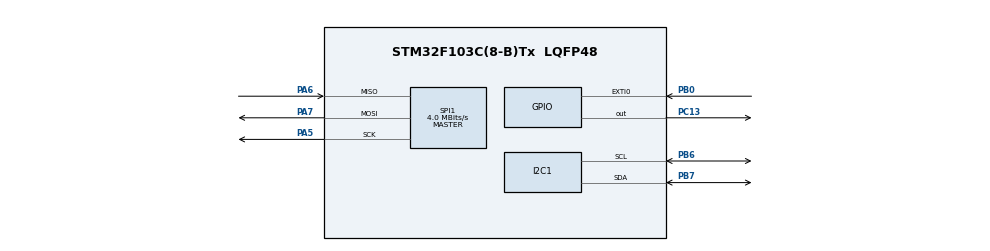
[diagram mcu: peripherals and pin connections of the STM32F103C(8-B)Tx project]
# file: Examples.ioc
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Dma.I2C1_RX.2.Direction=DMA_PERIPH_TO_MEMORY
Dma.I2C1_RX.2.Instance=DMA1_Channel7
Dma.I2C1_RX.2.MemDataAlignment=DMA_MDATAALIGN_BYTE
Dma.I2C1_RX.2.MemInc=DMA_MINC_ENABLE
Dma.I2C1_RX.2.Mode=DMA_NORMAL
Dma.I2C1_RX.2.PeriphDataAlignment=DMA_PDATAALIGN_BYTE
Dma.I2C1_RX.2.PeriphInc=DMA_PINC_DISABLE
Dma.I2C1_RX.2.Priority=DMA_PRIORITY_LOW
Dma.I2C1_TX.3.Direction=DMA_MEMORY_TO_PERIPH
Dma.I2C1_TX.3.Instance=DMA1_Channel6
Dma.I2C1_TX.3.MemDataAlignment=DMA_MDATAALIGN_BYTE
Dma.I2C1_TX.3.MemInc=DMA_MINC_ENABLE
Dma.I2C1_TX.3.Mode=DMA_NORMAL
Dma.I2C1_TX.3.PeriphDataAlignment=DMA_PDATAALIGN_BYTE
Dma.I2C1_TX.3.PeriphInc=DMA_PINC_DISABLE
Dma.I2C1_TX.3.Priority=DMA_PRIORITY_LOW
Dma.Request0=SPI1_RX
Dma.Request1=SPI1_TX
Dma.Request2=I2C1_RX
Dma.Request3=I2C1_TX
Dma.SPI1_RX.0.Direction=DMA_PERIPH_TO_MEMORY
Dma.SPI1_RX.0.Instance=DMA1_Channel2
Dma.SPI1_RX.0.MemDataAlignment=DMA_MDATAALIGN_BYTE
Dma.SPI1_RX.0.MemInc=DMA_MINC_ENABLE
Dma.SPI1_RX.0.Mode=DMA_NORMAL
Dma.SPI1_RX.0.PeriphDataAlignment=DMA_PDATAALIGN_BYTE
Dma.SPI1_RX.0.PeriphInc=DMA_PINC_DISABLE
Dma.SPI1_RX.0.Priority=DMA_PRIORITY_LOW
Dma.SPI1_TX.1.Direction=DMA_MEMORY_TO_PERIPH
Dma.SPI1_TX.1.Instance=DMA1_Channel3
Dma.SPI1_TX.1.MemDataAlignment=DMA_MDATAALIGN_BYTE
Dma.SPI1_TX.1.MemInc=DMA_MINC_ENABLE
Dma.SPI1_TX.1.Mode=DMA_NORMAL
Dma.SPI1_TX.1.PeriphDataAlignment=DMA_PDATAALIGN_BYTE
Dma.SPI1_TX.1.PeriphInc=DMA_PINC_DISABLE
Dma.SPI1_TX.1.Priority=DMA_PRIORITY_LOW
Mcu.Family=STM32F1
Mcu.Name=STM32F103C(8-B)Tx
Mcu.Package=LQFP48
NVIC.DMA1_Channel2_IRQn=true\:0\:0\:false\:false\:true\:false\:true\:true
NVIC.DMA1_Channel3_IRQn=true\:0\:0\:false\:false\:true\:false\:true\:true
NVIC.DMA1_Channel6_IRQn=true\:0\:0\:false\:false\:true\:false\:true\:true
NVIC.DMA1_Channel7_IRQn=true\:0\:0\:false\:false\:true\:false\:true\:true
NVIC.EXTI0_IRQn=true\:0\:0\:false\:false\:true\:true\:true\:true
NVIC.PriorityGroup=NVIC_PRIORITYGROUP_4
PA13.Mode=Serial_Wire
PA13.Signal=SYS_JTMS-SWDIO
PA14.Mode=Serial_Wire
PA14.Signal=SYS_JTCK-SWCLK
PA5.Mode=Full_Duplex_Master
PA5.Signal=SPI1_SCK
PA6.Mode=Full_Duplex_Master
PA6.Signal=SPI1_MISO
PA7.Mode=Full_Duplex_Master
PA7.Signal=SPI1_MOSI
PB0.GPIO_PuPd=GPIO_PULLUP
PB0.Signal=GPXTI0
PB6.Mode=I2C
PB6.Signal=I2C1_SCL
PB7.Mode=I2C
PB7.Signal=I2C1_SDA
PC13-TAMPER-RTC.Signal=GPIO_Output
PC14-OSC32_IN.Mode=LSE-External-Oscillator
PC14-OSC32_IN.Signal=RCC_OSC32_IN
PC15-OSC32_OUT.Mode=LSE-External-Oscillator
PC15-OSC32_OUT.Signal=RCC_OSC32_OUT
PD0-OSC_IN.Mode=HSE-External-Oscillator
PD0-OSC_IN.Signal=RCC_OSC_IN
PD1-OSC_OUT.Mode=HSE-External-Oscillator
PD1-OSC_OUT.Signal=RCC_OSC_OUT
ProjectManager.HeapSize=0x200
ProjectManager.StackSize=0x400
ProjectManager.TargetToolchain=STM32CubeIDE
RCC.APB1Freq_Value=8000000
RCC.APB2Freq_Value=8000000
SPI1.CalculateBaudRate=4.0 MBits/s
SPI1.Direction=SPI_DIRECTION_2LINES
SPI1.Mode=SPI_MODE_MASTER
SPI1.VirtualType=VM_MASTER
board=custom

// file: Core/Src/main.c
/* USER CODE BEGIN Header */
/**
  ******************************************************************************
  * @file           : main.c
  * @brief          : Main program body
  ******************************************************************************
  * @attention
  *
  * Copyright (c) 2022 STMicroelectronics.
  * All rights reserved.
  *
  * This software is licensed under terms that can be found in the LICENSE file
  * in the root directory of this software component.
  * If no LICENSE file comes with this software, it is provided AS-IS.
  *
  ******************************************************************************
  */
/* USER CODE END Header */
#include "main.h"

/* USER CODE BEGIN Includes */
#include <fd/fd_main.h>
/* USER CODE END Includes */

 I2C_HandleTypeDef hi2c1;
DMA_HandleTypeDef hdma_i2c1_rx;
DMA_HandleTypeDef hdma_i2c1_tx;

SPI_HandleTypeDef hspi1;
DMA_HandleTypeDef hdma_spi1_rx;
DMA_HandleTypeDef hdma_spi1_tx;

void SystemClock_Config(void);
static void MX_GPIO_Init(void);
static void MX_DMA_Init(void);
static void MX_SPI1_Init(void);
static void MX_I2C1_Init(void);

int main(void)
{

  /* MCU Configuration--------------------------------------------------------*/

  /* Reset of all peripherals, Initializes the Flash interface and the Systick. */
  HAL_Init();

  /* Configure the system clock */
  SystemClock_Config();

  /* Initialize all configured peripherals */
  MX_GPIO_Init();
  MX_DMA_Init();
  MX_SPI1_Init();
  MX_I2C1_Init();
  /* USER CODE BEGIN 2 */
    fd_main_caller();
  /* USER CODE END 2 */

  /* Infinite loop */
  while (1)
  {

  }
}

void SystemClock_Config(void)
{
  RCC_OscInitTypeDef RCC_OscInitStruct = {0};
  RCC_ClkInitTypeDef RCC_ClkInitStruct = {0};

  /** Initializes the RCC Oscillators according to the specified parameters
  * in the RCC_OscInitTypeDef structure.
  */
  RCC_OscInitStruct.OscillatorType = RCC_OSCILLATORTYPE_HSI;
  RCC_OscInitStruct.HSIState = RCC_HSI_ON;
  RCC_OscInitStruct.HSICalibrationValue = RCC_HSICALIBRATION_DEFAULT;
  RCC_OscInitStruct.PLL.PLLState = RCC_PLL_NONE;
  if (HAL_RCC_OscConfig(&RCC_OscInitStruct) != HAL_OK)
  {
    Error_Handler();
  }

  /** Initializes the CPU, AHB and APB buses clocks
  */
  RCC_ClkInitStruct.ClockType = RCC_CLOCKTYPE_HCLK|RCC_CLOCKTYPE_SYSCLK
                              |RCC_CLOCKTYPE_PCLK1|RCC_CLOCKTYPE_PCLK2;
  RCC_ClkInitStruct.SYSCLKSource = RCC_SYSCLKSOURCE_HSI;
  RCC_ClkInitStruct.AHBCLKDivider = RCC_SYSCLK_DIV1;
  RCC_ClkInitStruct.APB1CLKDivider = RCC_HCLK_DIV1;
  RCC_ClkInitStruct.APB2CLKDivider = RCC_HCLK_DIV1;

  if (HAL_RCC_ClockConfig(&RCC_ClkInitStruct, FLASH_LATENCY_0) != HAL_OK)
  {
    Error_Handler();
  }
}

static void MX_I2C1_Init(void)
{

  hi2c1.Instance = I2C1;
  hi2c1.Init.ClockSpeed = 100000;
  hi2c1.Init.DutyCycle = I2C_DUTYCYCLE_2;
  hi2c1.Init.OwnAddress1 = 0;
  hi2c1.Init.AddressingMode = I2C_ADDRESSINGMODE_7BIT;
  hi2c1.Init.DualAddressMode = I2C_DUALADDRESS_DISABLE;
  hi2c1.Init.OwnAddress2 = 0;
  hi2c1.Init.GeneralCallMode = I2C_GENERALCALL_DISABLE;
  hi2c1.Init.NoStretchMode = I2C_NOSTRETCH_DISABLE;
  if (HAL_I2C_Init(&hi2c1) != HAL_OK)
  {
    Error_Handler();
  }

}

static void MX_SPI1_Init(void)
{

  /* SPI1 parameter configuration*/
  hspi1.Instance = SPI1;
  hspi1.Init.Mode = SPI_MODE_MASTER;
  hspi1.Init.Direction = SPI_DIRECTION_2LINES;
  hspi1.Init.DataSize = SPI_DATASIZE_8BIT;
  hspi1.Init.CLKPolarity = SPI_POLARITY_LOW;
  hspi1.Init.CLKPhase = SPI_PHASE_1EDGE;
  hspi1.Init.NSS = SPI_NSS_SOFT;
  hspi1.Init.BaudRatePrescaler = SPI_BAUDRATEPRESCALER_2;
  hspi1.Init.FirstBit = SPI_FIRSTBIT_MSB;
  hspi1.Init.TIMode = SPI_TIMODE_DISABLE;
  hspi1.Init.CRCCalculation = SPI_CRCCALCULATION_DISABLE;
  hspi1.Init.CRCPolynomial = 10;
  if (HAL_SPI_Init(&hspi1) != HAL_OK)
  {
    Error_Handler();
  }

}

static void MX_DMA_Init(void)
{

  /* DMA controller clock enable */
  __HAL_RCC_DMA1_CLK_ENABLE();

  /* DMA interrupt init */
  /* DMA1_Channel2_IRQn interrupt configuration */
  HAL_NVIC_SetPriority(DMA1_Channel2_IRQn, 0, 0);
  HAL_NVIC_EnableIRQ(DMA1_Channel2_IRQn);
  /* DMA1_Channel3_IRQn interrupt configuration */
  HAL_NVIC_SetPriority(DMA1_Channel3_IRQn, 0, 0);
  HAL_NVIC_EnableIRQ(DMA1_Channel3_IRQn);
  /* DMA1_Channel6_IRQn interrupt configuration */
  HAL_NVIC_SetPriority(DMA1_Channel6_IRQn, 0, 0);
  HAL_NVIC_EnableIRQ(DMA1_Channel6_IRQn);
  /* DMA1_Channel7_IRQn interrupt configuration */
  HAL_NVIC_SetPriority(DMA1_Channel7_IRQn, 0, 0);
  HAL_NVIC_EnableIRQ(DMA1_Channel7_IRQn);

}

static void MX_GPIO_Init(void)
{
  GPIO_InitTypeDef GPIO_InitStruct = {0};

  /* GPIO Ports Clock Enable */
  __HAL_RCC_GPIOC_CLK_ENABLE();
  __HAL_RCC_GPIOD_CLK_ENABLE();
  __HAL_RCC_GPIOA_CLK_ENABLE();
  __HAL_RCC_GPIOB_CLK_ENABLE();

  /*Configure GPIO pin Output Level */
  HAL_GPIO_WritePin(GPIOC, GPIO_PIN_13, GPIO_PIN_RESET);

  /*Configure GPIO pin : PC13 */
  GPIO_InitStruct.Pin = GPIO_PIN_13;
  GPIO_InitStruct.Mode = GPIO_MODE_OUTPUT_PP;
  GPIO_InitStruct.Pull = GPIO_NOPULL;
  GPIO_InitStruct.Speed = GPIO_SPEED_FREQ_LOW;
  HAL_GPIO_Init(GPIOC, &GPIO_InitStruct);

  /*Configure GPIO pin : PB0 */
  GPIO_InitStruct.Pin = GPIO_PIN_0;
  GPIO_InitStruct.Mode = GPIO_MODE_IT_RISING;
  GPIO_InitStruct.Pull = GPIO_PULLUP;
  HAL_GPIO_Init(GPIOB, &GPIO_InitStruct);

  /* EXTI interrupt init*/
  HAL_NVIC_SetPriority(EXTI0_IRQn, 0, 0);
  HAL_NVIC_EnableIRQ(EXTI0_IRQn);

}

void Error_Handler(void)
{
  __disable_irq();
  while (1)
  {
  }
}
